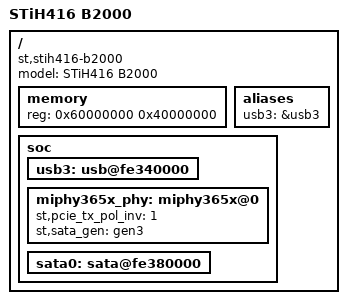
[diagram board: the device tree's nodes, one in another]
/*
 * Copyright (C) 2013 STMicroelectronics (R&D) Limited.
 * Author: Srinivas Kandagatla <srinivas.kandagatla@st.com>
 *
 * This program is free software; you can redistribute it and/or modify
 * it under the terms of the GNU General Public License version 2 as
 * publishhed by the Free Software Foundation.
 */
/dts-v1/;
#include "stih416.dtsi"
#include "stih41x-b2000.dtsi"

/ {
	model = "STiH416 B2000";
	compatible = "st,stih416-b2000", "st,stih416";

	memory {
		device_type = "memory";
		reg = <0x60000000 0x40000000>;
	};

	aliases {
		usb3 = &usb3;
	};

	soc {
		usb3: usb@fe340000 {
			status = "okay";
		};

		miphy365x_phy: miphy365x@0 {
			st,pcie_tx_pol_inv = <1>;
			st,sata_gen = "gen3";
		};

		sata0: sata@fe380000{
			status = "okay";
		};
	};
};
